# CTRL_MMR0_CFG0 register map
Vendor: Texas Instruments
Registers are 32-bit, read-write, reset 0x0 unless marked. A register's access mark holds for its fields unless they carry their own. Offsets are as the file gives them; [hi:lo] are bit positions; {n}, {i} and the like mark numbered series.

## CTRL_MMR0_CFG0 (part 8 of 10)
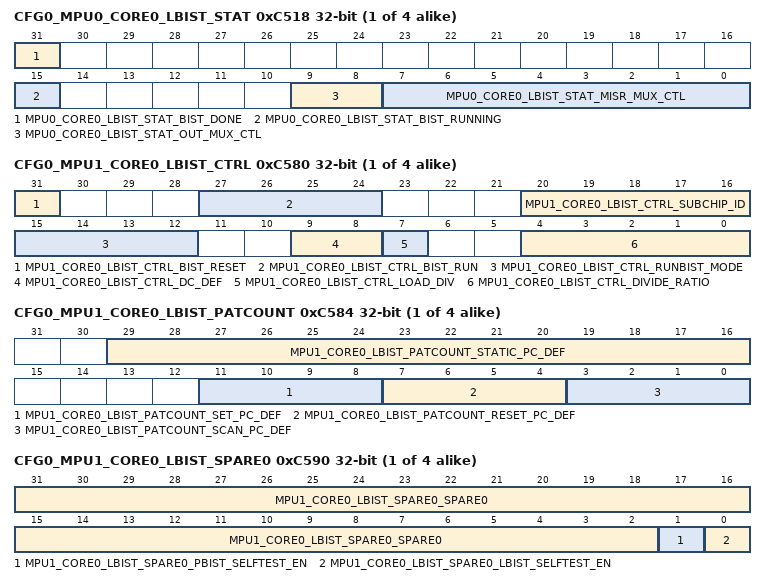
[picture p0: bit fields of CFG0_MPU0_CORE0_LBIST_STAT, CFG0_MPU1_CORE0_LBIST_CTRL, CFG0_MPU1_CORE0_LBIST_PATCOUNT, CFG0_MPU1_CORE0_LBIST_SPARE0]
{0xC518+0x20*i} CFG0_MPU0_CORE{i}_LBIST_STAT access per field (i=0..3) — Indicates LBIST status and provides MISR selection control
  [31] MPU0_CORE{i}_LBIST_STAT_BIST_DONE ro — LBIST is done
  [15] MPU0_CORE{i}_LBIST_STAT_BIST_RUNNING ro — LBIST is running
  [9:8] MPU0_CORE{i}_LBIST_STAT_OUT_MUX_CTL rw — Selects source of LBIST output 00 - LBIST IP PID value 01 - LBIST CTRL ID value 1x - MISR value
  [7:0] MPU0_CORE{i}_LBIST_STAT_MISR_MUX_CTL rw — Selects block of 32 MISR bits to read. A value of 0 selects a compacted 32-bit version of the full MISR. A value of 1-32 select a 32-bit segment of the MISR.
{0xC51C+0x20*i} CFG0_MPU0_CORE{i}_LBIST_MISR ro (i=0..3) — Contains LBIST MISR output value
  [31:0] MPU0_CORE{i}_LBIST_MISR_MISR_RESULT — 32-bits of MISR value selected by misr_mux_ctl
{0xC580+0x20*i} CFG0_MPU1_CORE{i}_LBIST_CTRL (i=0..3) — Configures and enables LBIST operation
  [31] MPU1_CORE{i}_LBIST_CTRL_BIST_RESET — Reset LBIST macro
  [27:24] MPU1_CORE{i}_LBIST_CTRL_BIST_RUN — Starts LBIST if all bits are 1
  [20:16] MPU1_CORE{i}_LBIST_CTRL_SUBCHIP_ID — Specifies which sub-chip is to be tested
  [15:12] MPU1_CORE{i}_LBIST_CTRL_RUNBIST_MODE — Runbist mode enable if all bits are 1
  [9:8] MPU1_CORE{i}_LBIST_CTRL_DC_DEF — Clock delay after scan_enable switching
  [7] MPU1_CORE{i}_LBIST_CTRL_LOAD_DIV — Loads LBIST clock divide ratio on transition from 0 to 1
  [4:0] MPU1_CORE{i}_LBIST_CTRL_DIVIDE_RATIO — LBIST clock divide ratio
{0xC584+0x20*i} CFG0_MPU1_CORE{i}_LBIST_PATCOUNT (i=0..3) — Specifies the number of LBIST patterns to run
  [29:16] MPU1_CORE{i}_LBIST_PATCOUNT_STATIC_PC_DEF — Number of stuck-at patterns to run
  [11:8] MPU1_CORE{i}_LBIST_PATCOUNT_SET_PC_DEF — Number of set patterns to run
  [7:4] MPU1_CORE{i}_LBIST_PATCOUNT_RESET_PC_DEF — Number of reset patterns to run
  [3:0] MPU1_CORE{i}_LBIST_PATCOUNT_SCAN_PC_DEF — Number of chain test patterns to run
{0xC588+0x20*i} CFG0_MPU1_CORE{i}_LBIST_SEED0 (i=0..3) — Specifies the 32 LSBs of the PRPG seed
  [31:0] MPU1_CORE{i}_LBIST_SEED0_PRPG_DEF — Initial seed for PRPG (bits 31:0)
{0xC58C+0x20*i} CFG0_MPU1_CORE{i}_LBIST_SEED1 (i=0..3) — Specifies the 21 MSBs of the PRPG seed
  [20:0] MPU1_CORE{i}_LBIST_SEED1_PRPG_DEF — Initial seed for PRPG (bits 52:32)
{0xC590+0x20*i} CFG0_MPU1_CORE{i}_LBIST_SPARE0 (i=0..3) — Spare LBIST control bits
  [31:2] MPU1_CORE{i}_LBIST_SPARE0_SPARE0 — LBIST spare bits
  [1] MPU1_CORE{i}_LBIST_SPARE0_PBIST_SELFTEST_EN — PBIST isolation control
  [0] MPU1_CORE{i}_LBIST_SPARE0_LBIST_SELFTEST_EN — LBIST isolation control
{0xC594+0x20*i} CFG0_MPU1_CORE{i}_LBIST_SPARE1 (i=0..3) — Spare LBIST control bits
  [31:0] MPU1_CORE{i}_LBIST_SPARE1_SPARE1 — LBIST spare bits
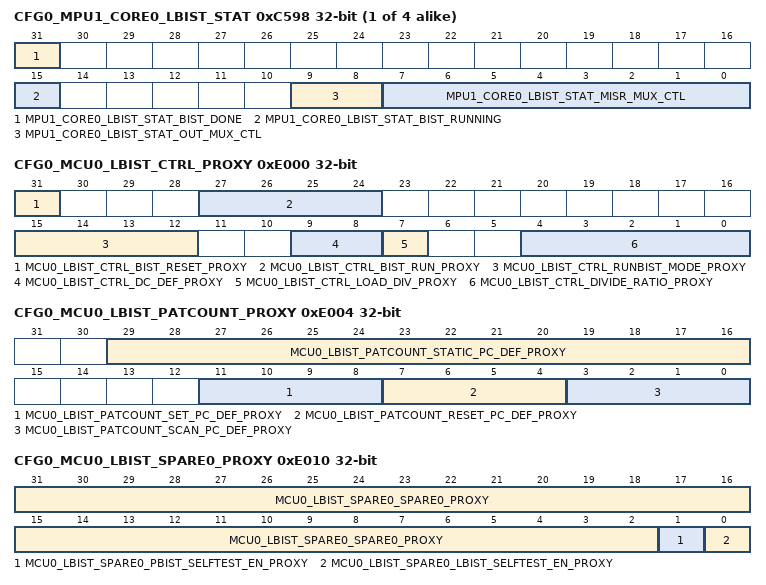
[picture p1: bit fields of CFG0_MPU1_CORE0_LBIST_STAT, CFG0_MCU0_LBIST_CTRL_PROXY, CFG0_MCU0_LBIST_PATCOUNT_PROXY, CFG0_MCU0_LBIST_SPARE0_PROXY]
{0xC598+0x20*i} CFG0_MPU1_CORE{i}_LBIST_STAT access per field (i=0..3) — Indicates LBIST status and provides MISR selection control
  [31] MPU1_CORE{i}_LBIST_STAT_BIST_DONE ro — LBIST is done
  [15] MPU1_CORE{i}_LBIST_STAT_BIST_RUNNING ro — LBIST is running
  [9:8] MPU1_CORE{i}_LBIST_STAT_OUT_MUX_CTL rw — Selects source of LBIST output 00 - LBIST IP PID value 01 - LBIST CTRL ID value 1x - MISR value
  [7:0] MPU1_CORE{i}_LBIST_STAT_MISR_MUX_CTL rw — Selects block of 32 MISR bits to read. A value of 0 selects a compacted 32-bit version of the full MISR. A value of 1-32 select a 32-bit segment of the MISR.
{0xC59C+0x20*i} CFG0_MPU1_CORE{i}_LBIST_MISR ro (i=0..3) — Contains LBIST MISR output value
  [31:0] MPU1_CORE{i}_LBIST_MISR_MISR_RESULT — 32-bits of MISR value selected by misr_mux_ctl
{0xC600+0x20*i} CFG0_MPU0_CORE{i}_LBIST_SIG ro (i=0..3) — Contains expected MISR output value
  [31:0] MPU0_CORE{i}_LBIST_SIG_MISR_SIG — MISR signature
{0xC680+0x20*i} CFG0_MPU1_CORE{i}_LBIST_SIG ro (i=0..3) — Contains expected MISR output value
  [31:0] MPU1_CORE{i}_LBIST_SIG_MISR_SIG — MISR signature
{0xD100+4i} CFG0_CLAIMREG_P3_R{i}_READONLY ro (i=0..13)
  [31:0] CLAIMREG_P3_R{i}_READONLY — Claim bits for Partition 3
0xE000 CFG0_MCU0_LBIST_CTRL_PROXY — Configures and enables LBIST operation
  [31] MCU0_LBIST_CTRL_BIST_RESET_PROXY — Reset LBIST macro
  [27:24] MCU0_LBIST_CTRL_BIST_RUN_PROXY — Starts LBIST if all bits are 1
  [15:12] MCU0_LBIST_CTRL_RUNBIST_MODE_PROXY — Runbist mode enable if all bits are 1
  [9:8] MCU0_LBIST_CTRL_DC_DEF_PROXY — Clock delay after scan_enable switching
  [7] MCU0_LBIST_CTRL_LOAD_DIV_PROXY — Loads LBIST clock divide ratio on transition from 0 to 1
  [4:0] MCU0_LBIST_CTRL_DIVIDE_RATIO_PROXY — LBIST clock divide ratio
0xE004 CFG0_MCU0_LBIST_PATCOUNT_PROXY — Specifies the number of LBIST patterns to run
  [29:16] MCU0_LBIST_PATCOUNT_STATIC_PC_DEF_PROXY — Number of stuck-at patterns to run
  [11:8] MCU0_LBIST_PATCOUNT_SET_PC_DEF_PROXY — Number of set patterns to run
  [7:4] MCU0_LBIST_PATCOUNT_RESET_PC_DEF_PROXY — Number of reset patterns to run
  [3:0] MCU0_LBIST_PATCOUNT_SCAN_PC_DEF_PROXY — Number of chain test patterns to run
0xE008 CFG0_MCU0_LBIST_SEED0_PROXY — Specifies the 32 LSBs of the PRPG seed
  [31:0] MCU0_LBIST_SEED0_PRPG_DEF_PROXY — Initial seed for PRPG (bits 31:0)
0xE00C CFG0_MCU0_LBIST_SEED1_PROXY — Specifies the 21 MSBs of the PRPG seed
  [20:0] MCU0_LBIST_SEED1_PRPG_DEF_PROXY — Initial seed for PRPG (bits 52:32)
0xE010 CFG0_MCU0_LBIST_SPARE0_PROXY — Spare LBIST control bits
  [31:2] MCU0_LBIST_SPARE0_SPARE0_PROXY — LBIST spare bits
  [1] MCU0_LBIST_SPARE0_PBIST_SELFTEST_EN_PROXY — PBIST isolation control
  [0] MCU0_LBIST_SPARE0_LBIST_SELFTEST_EN_PROXY — LBIST isolation control
0xE014 CFG0_MCU0_LBIST_SPARE1_PROXY — Spare LBIST control bits
  [31:0] MCU0_LBIST_SPARE1_SPARE1_PROXY — LBIST spare bits
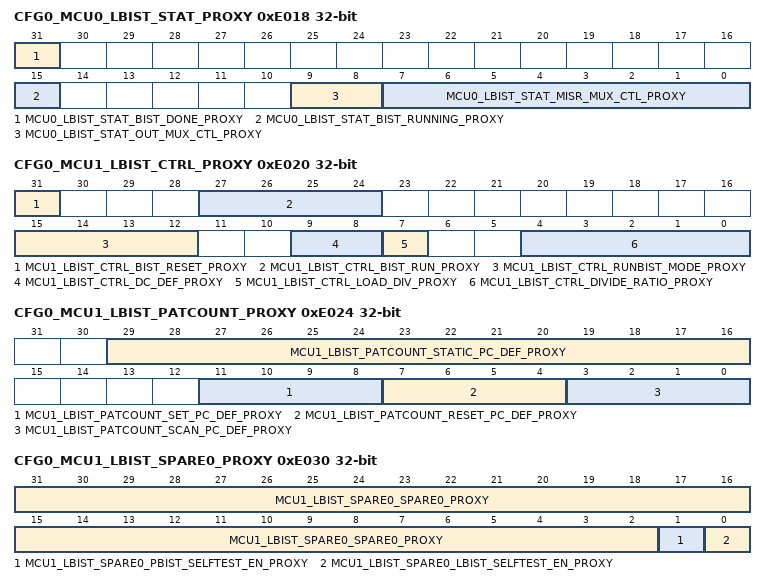
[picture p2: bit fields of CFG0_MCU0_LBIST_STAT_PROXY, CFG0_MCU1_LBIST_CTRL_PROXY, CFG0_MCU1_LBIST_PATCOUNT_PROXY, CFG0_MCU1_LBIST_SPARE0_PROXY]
0xE018 CFG0_MCU0_LBIST_STAT_PROXY access per field — Indicates LBIST status and provides MISR selection control
  [31] MCU0_LBIST_STAT_BIST_DONE_PROXY ro — LBIST is done
  [15] MCU0_LBIST_STAT_BIST_RUNNING_PROXY ro — LBIST is running
  [9:8] MCU0_LBIST_STAT_OUT_MUX_CTL_PROXY rw — Selects source of LBIST output 00 - LBIST IP PID value 01 - LBIST CTRL ID value 1x - MISR value
  [7:0] MCU0_LBIST_STAT_MISR_MUX_CTL_PROXY rw — Selects block of 32 MISR bits to read. A value of 0 selects a compacted 32-bit version of the full MISR. A value of 1-32 select a 32-bit segment of the MISR.
0xE01C CFG0_MCU0_LBIST_MISR_PROXY ro — Contains LBIST MISR output value
  [31:0] MCU0_LBIST_MISR_MISR_RESULT_PROXY — 32-bits of MISR value selected by misr_mux_ctl
0xE020 CFG0_MCU1_LBIST_CTRL_PROXY — Configures and enables LBIST operation
  [31] MCU1_LBIST_CTRL_BIST_RESET_PROXY — Reset LBIST macro
  [27:24] MCU1_LBIST_CTRL_BIST_RUN_PROXY — Starts LBIST if all bits are 1
  [15:12] MCU1_LBIST_CTRL_RUNBIST_MODE_PROXY — Runbist mode enable if all bits are 1
  [9:8] MCU1_LBIST_CTRL_DC_DEF_PROXY — Clock delay after scan_enable switching
  [7] MCU1_LBIST_CTRL_LOAD_DIV_PROXY — Loads LBIST clock divide ratio on transition from 0 to 1
  [4:0] MCU1_LBIST_CTRL_DIVIDE_RATIO_PROXY — LBIST clock divide ratio
0xE024 CFG0_MCU1_LBIST_PATCOUNT_PROXY — Specifies the number of LBIST patterns to run
  [29:16] MCU1_LBIST_PATCOUNT_STATIC_PC_DEF_PROXY — Number of stuck-at patterns to run
  [11:8] MCU1_LBIST_PATCOUNT_SET_PC_DEF_PROXY — Number of set patterns to run
  [7:4] MCU1_LBIST_PATCOUNT_RESET_PC_DEF_PROXY — Number of reset patterns to run
  [3:0] MCU1_LBIST_PATCOUNT_SCAN_PC_DEF_PROXY — Number of chain test patterns to run
0xE028 CFG0_MCU1_LBIST_SEED0_PROXY — Specifies the 32 LSBs of the PRPG seed
  [31:0] MCU1_LBIST_SEED0_PRPG_DEF_PROXY — Initial seed for PRPG (bits 31:0)
0xE02C CFG0_MCU1_LBIST_SEED1_PROXY — Specifies the 21 MSBs of the PRPG seed
  [20:0] MCU1_LBIST_SEED1_PRPG_DEF_PROXY — Initial seed for PRPG (bits 52:32)
0xE030 CFG0_MCU1_LBIST_SPARE0_PROXY — Spare LBIST control bits
  [31:2] MCU1_LBIST_SPARE0_SPARE0_PROXY — LBIST spare bits
  [1] MCU1_LBIST_SPARE0_PBIST_SELFTEST_EN_PROXY — PBIST isolation control
  [0] MCU1_LBIST_SPARE0_LBIST_SELFTEST_EN_PROXY — LBIST isolation control
0xE034 CFG0_MCU1_LBIST_SPARE1_PROXY — Spare LBIST control bits
  [31:0] MCU1_LBIST_SPARE1_SPARE1_PROXY — LBIST spare bits
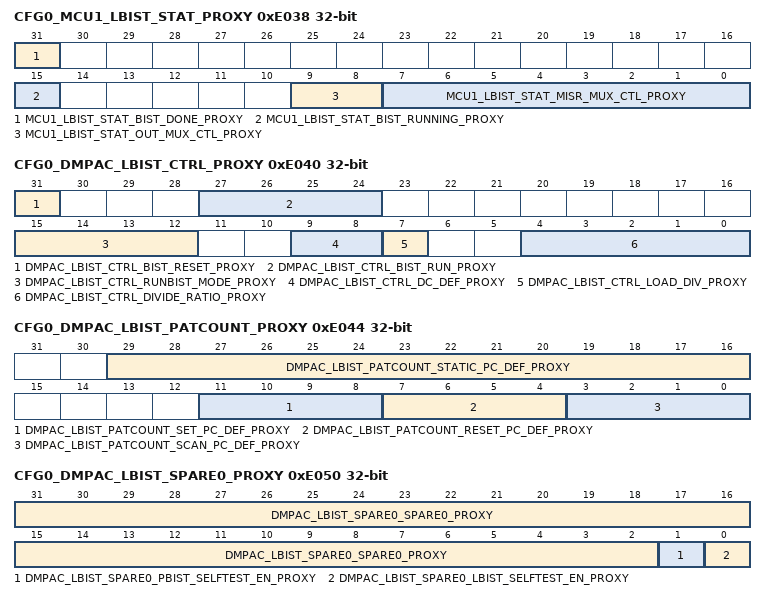
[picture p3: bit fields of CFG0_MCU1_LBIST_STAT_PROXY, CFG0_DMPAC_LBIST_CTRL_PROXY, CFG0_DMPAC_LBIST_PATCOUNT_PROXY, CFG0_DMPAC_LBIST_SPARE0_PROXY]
0xE038 CFG0_MCU1_LBIST_STAT_PROXY access per field — Indicates LBIST status and provides MISR selection control
  [31] MCU1_LBIST_STAT_BIST_DONE_PROXY ro — LBIST is done
  [15] MCU1_LBIST_STAT_BIST_RUNNING_PROXY ro — LBIST is running
  [9:8] MCU1_LBIST_STAT_OUT_MUX_CTL_PROXY rw — Selects source of LBIST output 00 - LBIST IP PID value 01 - LBIST CTRL ID value 1x - MISR value
  [7:0] MCU1_LBIST_STAT_MISR_MUX_CTL_PROXY rw — Selects block of 32 MISR bits to read. A value of 0 selects a compacted 32-bit version of the full MISR. A value of 1-32 select a 32-bit segment of the MISR.
0xE03C CFG0_MCU1_LBIST_MISR_PROXY ro — Contains LBIST MISR output value
  [31:0] MCU1_LBIST_MISR_MISR_RESULT_PROXY — 32-bits of MISR value selected by misr_mux_ctl
0xE040 CFG0_DMPAC_LBIST_CTRL_PROXY — Configures and enables LBIST operation
  [31] DMPAC_LBIST_CTRL_BIST_RESET_PROXY — Reset LBIST macro
  [27:24] DMPAC_LBIST_CTRL_BIST_RUN_PROXY — Starts LBIST if all bits are 1
  [15:12] DMPAC_LBIST_CTRL_RUNBIST_MODE_PROXY — Runbist mode enable if all bits are 1
  [9:8] DMPAC_LBIST_CTRL_DC_DEF_PROXY — Clock delay after scan_enable switching
  [7] DMPAC_LBIST_CTRL_LOAD_DIV_PROXY — Loads LBIST clock divide ratio on transition from 0 to 1
  [4:0] DMPAC_LBIST_CTRL_DIVIDE_RATIO_PROXY — LBIST clock divide ratio
0xE044 CFG0_DMPAC_LBIST_PATCOUNT_PROXY — Specifies the number of LBIST patterns to run
  [29:16] DMPAC_LBIST_PATCOUNT_STATIC_PC_DEF_PROXY — Number of stuck-at patterns to run
  [11:8] DMPAC_LBIST_PATCOUNT_SET_PC_DEF_PROXY — Number of set patterns to run
  [7:4] DMPAC_LBIST_PATCOUNT_RESET_PC_DEF_PROXY — Number of reset patterns to run
  [3:0] DMPAC_LBIST_PATCOUNT_SCAN_PC_DEF_PROXY — Number of chain test patterns to run
0xE048 CFG0_DMPAC_LBIST_SEED0_PROXY — Specifies the 32 LSBs of the PRPG seed
  [31:0] DMPAC_LBIST_SEED0_PRPG_DEF_PROXY — Initial seed for PRPG (bits 31:0)
0xE04C CFG0_DMPAC_LBIST_SEED1_PROXY — Specifies the 21 MSBs of the PRPG seed
  [20:0] DMPAC_LBIST_SEED1_PRPG_DEF_PROXY — Initial seed for PRPG (bits 52:32)
0xE050 CFG0_DMPAC_LBIST_SPARE0_PROXY — Spare LBIST control bits
  [31:2] DMPAC_LBIST_SPARE0_SPARE0_PROXY — LBIST spare bits
  [1] DMPAC_LBIST_SPARE0_PBIST_SELFTEST_EN_PROXY — PBIST isolation control
  [0] DMPAC_LBIST_SPARE0_LBIST_SELFTEST_EN_PROXY — LBIST isolation control
0xE054 CFG0_DMPAC_LBIST_SPARE1_PROXY — Spare LBIST control bits
  [31:0] DMPAC_LBIST_SPARE1_SPARE1_PROXY — LBIST spare bits
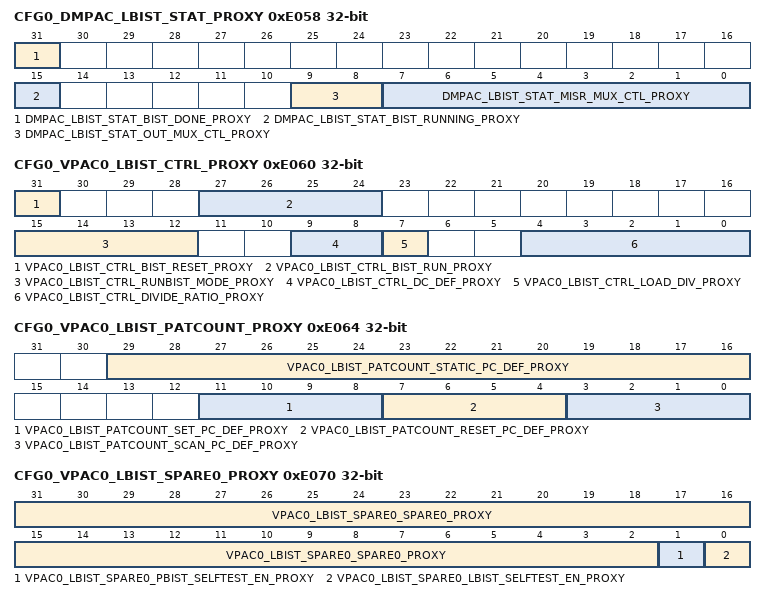
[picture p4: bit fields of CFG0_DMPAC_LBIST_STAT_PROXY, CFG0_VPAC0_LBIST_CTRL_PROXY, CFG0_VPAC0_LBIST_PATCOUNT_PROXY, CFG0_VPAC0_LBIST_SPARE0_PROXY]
0xE058 CFG0_DMPAC_LBIST_STAT_PROXY access per field — Indicates LBIST status and provides MISR selection control
  [31] DMPAC_LBIST_STAT_BIST_DONE_PROXY ro — LBIST is done
  [15] DMPAC_LBIST_STAT_BIST_RUNNING_PROXY ro — LBIST is running
  [9:8] DMPAC_LBIST_STAT_OUT_MUX_CTL_PROXY rw — Selects source of LBIST output 00 - LBIST IP PID value 01 - LBIST CTRL ID value 1x - MISR value
  [7:0] DMPAC_LBIST_STAT_MISR_MUX_CTL_PROXY rw — Selects block of 32 MISR bits to read. A value of 0 selects a compacted 32-bit version of the full MISR. A value of 1-32 select a 32-bit segment of the MISR.
0xE05C CFG0_DMPAC_LBIST_MISR_PROXY ro — Contains LBIST MISR output value
  [31:0] DMPAC_LBIST_MISR_MISR_RESULT_PROXY — 32-bits of MISR value selected by misr_mux_ctl
0xE060 CFG0_VPAC0_LBIST_CTRL_PROXY — Configures and enables LBIST operation
  [31] VPAC0_LBIST_CTRL_BIST_RESET_PROXY — Reset LBIST macro
  [27:24] VPAC0_LBIST_CTRL_BIST_RUN_PROXY — Starts LBIST if all bits are 1
  [15:12] VPAC0_LBIST_CTRL_RUNBIST_MODE_PROXY — Runbist mode enable if all bits are 1
  [9:8] VPAC0_LBIST_CTRL_DC_DEF_PROXY — Clock delay after scan_enable switching
  [7] VPAC0_LBIST_CTRL_LOAD_DIV_PROXY — Loads LBIST clock divide ratio on transition from 0 to 1
  [4:0] VPAC0_LBIST_CTRL_DIVIDE_RATIO_PROXY — LBIST clock divide ratio
0xE064 CFG0_VPAC0_LBIST_PATCOUNT_PROXY — Specifies the number of LBIST patterns to run
  [29:16] VPAC0_LBIST_PATCOUNT_STATIC_PC_DEF_PROXY — Number of stuck-at patterns to run
  [11:8] VPAC0_LBIST_PATCOUNT_SET_PC_DEF_PROXY — Number of set patterns to run
  [7:4] VPAC0_LBIST_PATCOUNT_RESET_PC_DEF_PROXY — Number of reset patterns to run
  [3:0] VPAC0_LBIST_PATCOUNT_SCAN_PC_DEF_PROXY — Number of chain test patterns to run
0xE068 CFG0_VPAC0_LBIST_SEED0_PROXY — Specifies the 32 LSBs of the PRPG seed
  [31:0] VPAC0_LBIST_SEED0_PRPG_DEF_PROXY — Initial seed for PRPG (bits 31:0)
0xE06C CFG0_VPAC0_LBIST_SEED1_PROXY — Specifies the 21 MSBs of the PRPG seed
  [20:0] VPAC0_LBIST_SEED1_PRPG_DEF_PROXY — Initial seed for PRPG (bits 52:32)
0xE070 CFG0_VPAC0_LBIST_SPARE0_PROXY — Spare LBIST control bits
  [31:2] VPAC0_LBIST_SPARE0_SPARE0_PROXY — LBIST spare bits
  [1] VPAC0_LBIST_SPARE0_PBIST_SELFTEST_EN_PROXY — PBIST isolation control
  [0] VPAC0_LBIST_SPARE0_LBIST_SELFTEST_EN_PROXY — LBIST isolation control
0xE074 CFG0_VPAC0_LBIST_SPARE1_PROXY — Spare LBIST control bits
  [31:0] VPAC0_LBIST_SPARE1_SPARE1_PROXY — LBIST spare bits
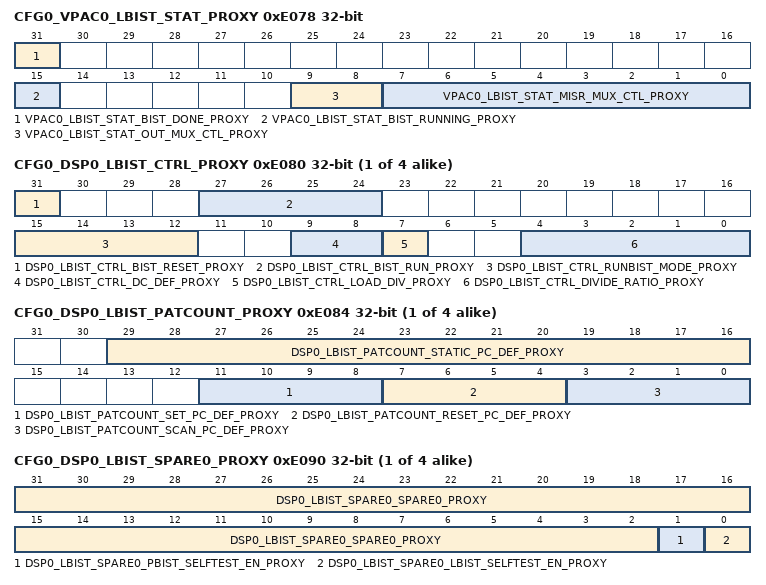
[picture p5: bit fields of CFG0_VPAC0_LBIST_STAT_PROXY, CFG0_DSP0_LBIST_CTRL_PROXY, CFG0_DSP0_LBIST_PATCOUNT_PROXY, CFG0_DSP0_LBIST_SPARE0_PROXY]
0xE078 CFG0_VPAC0_LBIST_STAT_PROXY access per field — Indicates LBIST status and provides MISR selection control
  [31] VPAC0_LBIST_STAT_BIST_DONE_PROXY ro — LBIST is done
  [15] VPAC0_LBIST_STAT_BIST_RUNNING_PROXY ro — LBIST is running
  [9:8] VPAC0_LBIST_STAT_OUT_MUX_CTL_PROXY rw — Selects source of LBIST output 00 - LBIST IP PID value 01 - LBIST CTRL ID value 1x - MISR value
  [7:0] VPAC0_LBIST_STAT_MISR_MUX_CTL_PROXY rw — Selects block of 32 MISR bits to read. A value of 0 selects a compacted 32-bit version of the full MISR. A value of 1-32 select a 32-bit segment of the MISR.
0xE07C CFG0_VPAC0_LBIST_MISR_PROXY ro — Contains LBIST MISR output value
  [31:0] VPAC0_LBIST_MISR_MISR_RESULT_PROXY — 32-bits of MISR value selected by misr_mux_ctl
{0xE080+0x20*i} CFG0_DSP{i}_LBIST_CTRL_PROXY (i=0..3) — Configures and enables LBIST operation
  [31] DSP{i}_LBIST_CTRL_BIST_RESET_PROXY — Reset LBIST macro
  [27:24] DSP{i}_LBIST_CTRL_BIST_RUN_PROXY — Starts LBIST if all bits are 1
  [15:12] DSP{i}_LBIST_CTRL_RUNBIST_MODE_PROXY — Runbist mode enable if all bits are 1
  [9:8] DSP{i}_LBIST_CTRL_DC_DEF_PROXY — Clock delay after scan_enable switching
  [7] DSP{i}_LBIST_CTRL_LOAD_DIV_PROXY — Loads LBIST clock divide ratio on transition from 0 to 1
  [4:0] DSP{i}_LBIST_CTRL_DIVIDE_RATIO_PROXY — LBIST clock divide ratio
{0xE084+0x20*i} CFG0_DSP{i}_LBIST_PATCOUNT_PROXY (i=0..3) — Specifies the number of LBIST patterns to run
  [29:16] DSP{i}_LBIST_PATCOUNT_STATIC_PC_DEF_PROXY — Number of stuck-at patterns to run
  [11:8] DSP{i}_LBIST_PATCOUNT_SET_PC_DEF_PROXY — Number of set patterns to run
  [7:4] DSP{i}_LBIST_PATCOUNT_RESET_PC_DEF_PROXY — Number of reset patterns to run
  [3:0] DSP{i}_LBIST_PATCOUNT_SCAN_PC_DEF_PROXY — Number of chain test patterns to run
{0xE088+0x20*i} CFG0_DSP{i}_LBIST_SEED0_PROXY (i=0..3) — Specifies the 32 LSBs of the PRPG seed
  [31:0] DSP{i}_LBIST_SEED0_PRPG_DEF_PROXY — Initial seed for PRPG (bits 31:0)
{0xE08C+0x20*i} CFG0_DSP{i}_LBIST_SEED1_PROXY (i=0..3) — Specifies the 21 MSBs of the PRPG seed
  [20:0] DSP{i}_LBIST_SEED1_PRPG_DEF_PROXY — Initial seed for PRPG (bits 52:32)
{0xE090+0x20*i} CFG0_DSP{i}_LBIST_SPARE0_PROXY (i=0..3) — Spare LBIST control bits
  [31:2] DSP{i}_LBIST_SPARE0_SPARE0_PROXY — LBIST spare bits
  [1] DSP{i}_LBIST_SPARE0_PBIST_SELFTEST_EN_PROXY — PBIST isolation control
  [0] DSP{i}_LBIST_SPARE0_LBIST_SELFTEST_EN_PROXY — LBIST isolation control
{0xE094+0x20*i} CFG0_DSP{i}_LBIST_SPARE1_PROXY (i=0..3) — Spare LBIST control bits
  [31:0] DSP{i}_LBIST_SPARE1_SPARE1_PROXY — LBIST spare bits
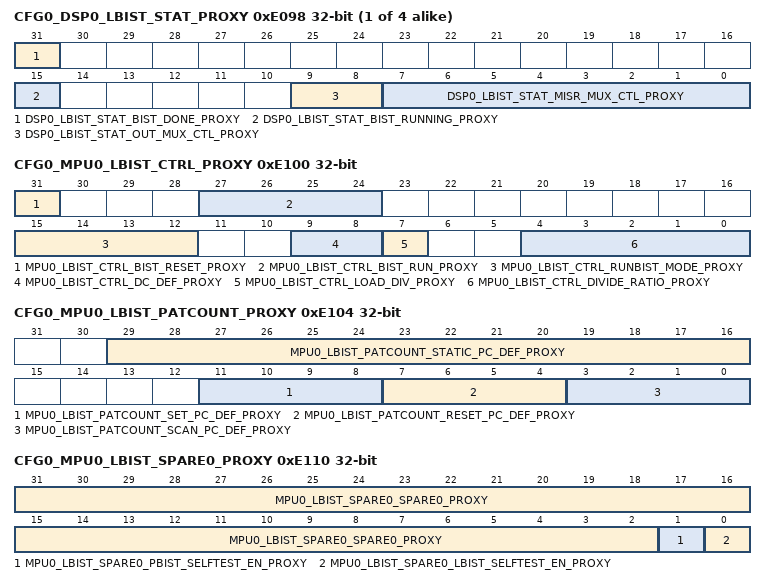
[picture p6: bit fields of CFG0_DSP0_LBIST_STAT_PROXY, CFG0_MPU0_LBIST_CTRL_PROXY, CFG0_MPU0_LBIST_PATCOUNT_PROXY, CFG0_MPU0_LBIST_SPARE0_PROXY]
{0xE098+0x20*i} CFG0_DSP{i}_LBIST_STAT_PROXY access per field (i=0..3) — Indicates LBIST status and provides MISR selection control
  [31] DSP{i}_LBIST_STAT_BIST_DONE_PROXY ro — LBIST is done
  [15] DSP{i}_LBIST_STAT_BIST_RUNNING_PROXY ro — LBIST is running
  [9:8] DSP{i}_LBIST_STAT_OUT_MUX_CTL_PROXY rw — Selects source of LBIST output 00 - LBIST IP PID value 01 - LBIST CTRL ID value 1x - MISR value
  [7:0] DSP{i}_LBIST_STAT_MISR_MUX_CTL_PROXY rw — Selects block of 32 MISR bits to read. A value of 0 selects a compacted 32-bit version of the full MISR. A value of 1-32 select a 32-bit segment of the MISR.
{0xE09C+0x20*i} CFG0_DSP{i}_LBIST_MISR_PROXY ro (i=0..3) — Contains LBIST MISR output value
  [31:0] DSP{i}_LBIST_MISR_MISR_RESULT_PROXY — 32-bits of MISR value selected by misr_mux_ctl
0xE100 CFG0_MPU0_LBIST_CTRL_PROXY — Configures and enables LBIST operation
  [31] MPU0_LBIST_CTRL_BIST_RESET_PROXY — Reset LBIST macro
  [27:24] MPU0_LBIST_CTRL_BIST_RUN_PROXY — Starts LBIST if all bits are 1
  [15:12] MPU0_LBIST_CTRL_RUNBIST_MODE_PROXY — Runbist mode enable if all bits are 1
  [9:8] MPU0_LBIST_CTRL_DC_DEF_PROXY — Clock delay after scan_enable switching
  [7] MPU0_LBIST_CTRL_LOAD_DIV_PROXY — Loads LBIST clock divide ratio on transition from 0 to 1
  [4:0] MPU0_LBIST_CTRL_DIVIDE_RATIO_PROXY — LBIST clock divide ratio
0xE104 CFG0_MPU0_LBIST_PATCOUNT_PROXY — Specifies the number of LBIST patterns to run
  [29:16] MPU0_LBIST_PATCOUNT_STATIC_PC_DEF_PROXY — Number of stuck-at patterns to run
  [11:8] MPU0_LBIST_PATCOUNT_SET_PC_DEF_PROXY — Number of set patterns to run
  [7:4] MPU0_LBIST_PATCOUNT_RESET_PC_DEF_PROXY — Number of reset patterns to run
  [3:0] MPU0_LBIST_PATCOUNT_SCAN_PC_DEF_PROXY — Number of chain test patterns to run
0xE108 CFG0_MPU0_LBIST_SEED0_PROXY — Specifies the 32 LSBs of the PRPG seed
  [31:0] MPU0_LBIST_SEED0_PRPG_DEF_PROXY — Initial seed for PRPG (bits 31:0)
0xE10C CFG0_MPU0_LBIST_SEED1_PROXY — Specifies the 21 MSBs of the PRPG seed
  [20:0] MPU0_LBIST_SEED1_PRPG_DEF_PROXY — Initial seed for PRPG (bits 52:32)
0xE110 CFG0_MPU0_LBIST_SPARE0_PROXY — Spare LBIST control bits
  [31:2] MPU0_LBIST_SPARE0_SPARE0_PROXY — LBIST spare bits
  [1] MPU0_LBIST_SPARE0_PBIST_SELFTEST_EN_PROXY — PBIST isolation control
  [0] MPU0_LBIST_SPARE0_LBIST_SELFTEST_EN_PROXY — LBIST isolation control
0xE114 CFG0_MPU0_LBIST_SPARE1_PROXY — Spare LBIST control bits
  [31:0] MPU0_LBIST_SPARE1_SPARE1_PROXY — LBIST spare bits
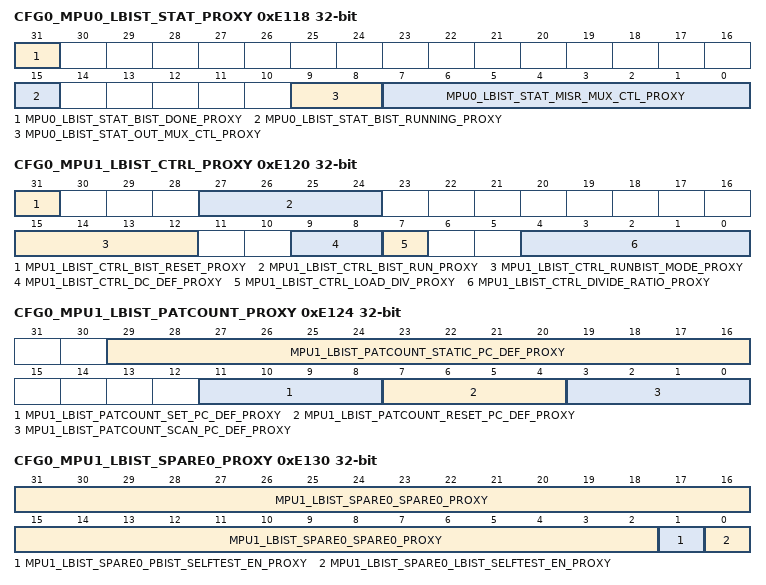
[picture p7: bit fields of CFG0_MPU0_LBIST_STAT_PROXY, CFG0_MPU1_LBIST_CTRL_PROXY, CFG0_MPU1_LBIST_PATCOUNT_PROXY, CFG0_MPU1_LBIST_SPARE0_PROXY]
0xE118 CFG0_MPU0_LBIST_STAT_PROXY access per field — Indicates LBIST status and provides MISR selection control
  [31] MPU0_LBIST_STAT_BIST_DONE_PROXY ro — LBIST is done
  [15] MPU0_LBIST_STAT_BIST_RUNNING_PROXY ro — LBIST is running
  [9:8] MPU0_LBIST_STAT_OUT_MUX_CTL_PROXY rw — Selects source of LBIST output 00 - LBIST IP PID value 01 - LBIST CTRL ID value 1x - MISR value
  [7:0] MPU0_LBIST_STAT_MISR_MUX_CTL_PROXY rw — Selects block of 32 MISR bits to read. A value of 0 selects a compacted 32-bit version of the full MISR. A value of 1-32 select a 32-bit segment of the MISR.
0xE11C CFG0_MPU0_LBIST_MISR_PROXY ro — Contains LBIST MISR output value
  [31:0] MPU0_LBIST_MISR_MISR_RESULT_PROXY — 32-bits of MISR value selected by misr_mux_ctl
0xE120 CFG0_MPU1_LBIST_CTRL_PROXY — Configures and enables LBIST operation
  [31] MPU1_LBIST_CTRL_BIST_RESET_PROXY — Reset LBIST macro
  [27:24] MPU1_LBIST_CTRL_BIST_RUN_PROXY — Starts LBIST if all bits are 1
  [15:12] MPU1_LBIST_CTRL_RUNBIST_MODE_PROXY — Runbist mode enable if all bits are 1
  [9:8] MPU1_LBIST_CTRL_DC_DEF_PROXY — Clock delay after scan_enable switching
  [7] MPU1_LBIST_CTRL_LOAD_DIV_PROXY — Loads LBIST clock divide ratio on transition from 0 to 1
  [4:0] MPU1_LBIST_CTRL_DIVIDE_RATIO_PROXY — LBIST clock divide ratio
0xE124 CFG0_MPU1_LBIST_PATCOUNT_PROXY — Specifies the number of LBIST patterns to run
  [29:16] MPU1_LBIST_PATCOUNT_STATIC_PC_DEF_PROXY — Number of stuck-at patterns to run
  [11:8] MPU1_LBIST_PATCOUNT_SET_PC_DEF_PROXY — Number of set patterns to run
  [7:4] MPU1_LBIST_PATCOUNT_RESET_PC_DEF_PROXY — Number of reset patterns to run
  [3:0] MPU1_LBIST_PATCOUNT_SCAN_PC_DEF_PROXY — Number of chain test patterns to run
0xE128 CFG0_MPU1_LBIST_SEED0_PROXY — Specifies the 32 LSBs of the PRPG seed
  [31:0] MPU1_LBIST_SEED0_PRPG_DEF_PROXY — Initial seed for PRPG (bits 31:0)
0xE12C CFG0_MPU1_LBIST_SEED1_PROXY — Specifies the 21 MSBs of the PRPG seed
  [20:0] MPU1_LBIST_SEED1_PRPG_DEF_PROXY — Initial seed for PRPG (bits 52:32)
0xE130 CFG0_MPU1_LBIST_SPARE0_PROXY — Spare LBIST control bits
  [31:2] MPU1_LBIST_SPARE0_SPARE0_PROXY — LBIST spare bits
  [1] MPU1_LBIST_SPARE0_PBIST_SELFTEST_EN_PROXY — PBIST isolation control
  [0] MPU1_LBIST_SPARE0_LBIST_SELFTEST_EN_PROXY — LBIST isolation control
0xE134 CFG0_MPU1_LBIST_SPARE1_PROXY — Spare LBIST control bits
  [31:0] MPU1_LBIST_SPARE1_SPARE1_PROXY — LBIST spare bits
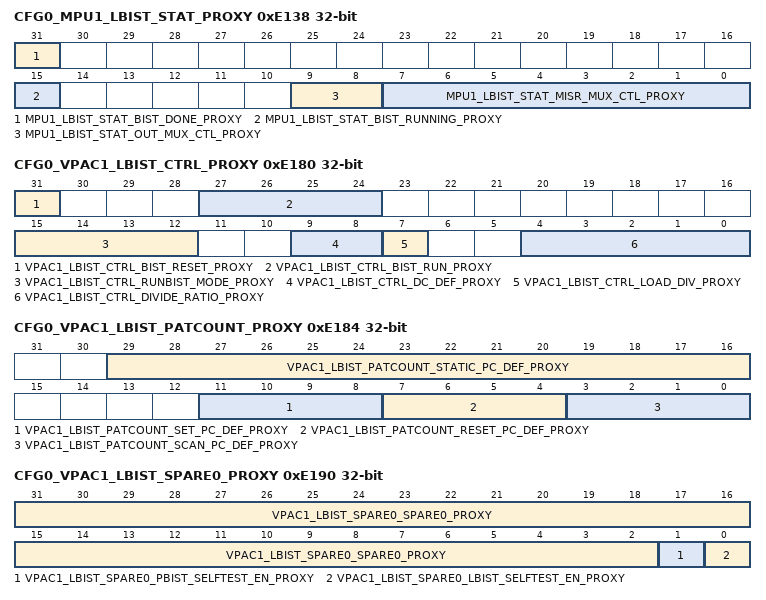
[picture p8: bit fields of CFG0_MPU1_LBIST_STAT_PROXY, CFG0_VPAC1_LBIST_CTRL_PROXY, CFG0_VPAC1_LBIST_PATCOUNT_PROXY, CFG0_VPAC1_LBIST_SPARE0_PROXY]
0xE138 CFG0_MPU1_LBIST_STAT_PROXY access per field — Indicates LBIST status and provides MISR selection control
  [31] MPU1_LBIST_STAT_BIST_DONE_PROXY ro — LBIST is done
  [15] MPU1_LBIST_STAT_BIST_RUNNING_PROXY ro — LBIST is running
  [9:8] MPU1_LBIST_STAT_OUT_MUX_CTL_PROXY rw — Selects source of LBIST output 00 - LBIST IP PID value 01 - LBIST CTRL ID value 1x - MISR value
  [7:0] MPU1_LBIST_STAT_MISR_MUX_CTL_PROXY rw — Selects block of 32 MISR bits to read. A value of 0 selects a compacted 32-bit version of the full MISR. A value of 1-32 select a 32-bit segment of the MISR.
0xE13C CFG0_MPU1_LBIST_MISR_PROXY ro — Contains LBIST MISR output value
  [31:0] MPU1_LBIST_MISR_MISR_RESULT_PROXY — 32-bits of MISR value selected by misr_mux_ctl
0xE180 CFG0_VPAC1_LBIST_CTRL_PROXY — Configures and enables LBIST operation
  [31] VPAC1_LBIST_CTRL_BIST_RESET_PROXY — Reset LBIST macro
  [27:24] VPAC1_LBIST_CTRL_BIST_RUN_PROXY — Starts LBIST if all bits are 1
  [15:12] VPAC1_LBIST_CTRL_RUNBIST_MODE_PROXY — Runbist mode enable if all bits are 1
  [9:8] VPAC1_LBIST_CTRL_DC_DEF_PROXY — Clock delay after scan_enable switching
  [7] VPAC1_LBIST_CTRL_LOAD_DIV_PROXY — Loads LBIST clock divide ratio on transition from 0 to 1
  [4:0] VPAC1_LBIST_CTRL_DIVIDE_RATIO_PROXY — LBIST clock divide ratio
0xE184 CFG0_VPAC1_LBIST_PATCOUNT_PROXY — Specifies the number of LBIST patterns to run
  [29:16] VPAC1_LBIST_PATCOUNT_STATIC_PC_DEF_PROXY — Number of stuck-at patterns to run
  [11:8] VPAC1_LBIST_PATCOUNT_SET_PC_DEF_PROXY — Number of set patterns to run
  [7:4] VPAC1_LBIST_PATCOUNT_RESET_PC_DEF_PROXY — Number of reset patterns to run
  [3:0] VPAC1_LBIST_PATCOUNT_SCAN_PC_DEF_PROXY — Number of chain test patterns to run
0xE188 CFG0_VPAC1_LBIST_SEED0_PROXY — Specifies the 32 LSBs of the PRPG seed
  [31:0] VPAC1_LBIST_SEED0_PRPG_DEF_PROXY — Initial seed for PRPG (bits 31:0)
0xE18C CFG0_VPAC1_LBIST_SEED1_PROXY — Specifies the 21 MSBs of the PRPG seed
  [20:0] VPAC1_LBIST_SEED1_PRPG_DEF_PROXY — Initial seed for PRPG (bits 52:32)
0xE190 CFG0_VPAC1_LBIST_SPARE0_PROXY — Spare LBIST control bits
  [31:2] VPAC1_LBIST_SPARE0_SPARE0_PROXY — LBIST spare bits
  [1] VPAC1_LBIST_SPARE0_PBIST_SELFTEST_EN_PROXY — PBIST isolation control
  [0] VPAC1_LBIST_SPARE0_LBIST_SELFTEST_EN_PROXY — LBIST isolation control
0xE194 CFG0_VPAC1_LBIST_SPARE1_PROXY — Spare LBIST control bits
  [31:0] VPAC1_LBIST_SPARE1_SPARE1_PROXY — LBIST spare bits
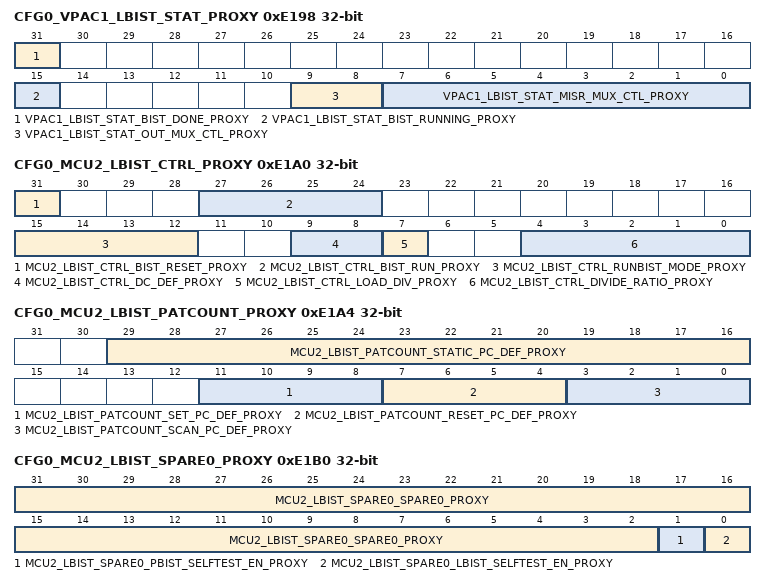
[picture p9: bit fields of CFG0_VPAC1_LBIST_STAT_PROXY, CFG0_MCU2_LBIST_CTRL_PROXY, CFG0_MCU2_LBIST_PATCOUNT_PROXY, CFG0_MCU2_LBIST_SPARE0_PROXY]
0xE198 CFG0_VPAC1_LBIST_STAT_PROXY access per field — Indicates LBIST status and provides MISR selection control
  [31] VPAC1_LBIST_STAT_BIST_DONE_PROXY ro — LBIST is done
  [15] VPAC1_LBIST_STAT_BIST_RUNNING_PROXY ro — LBIST is running
  [9:8] VPAC1_LBIST_STAT_OUT_MUX_CTL_PROXY rw — Selects source of LBIST output 00 - LBIST IP PID value 01 - LBIST CTRL ID value 1x - MISR value
  [7:0] VPAC1_LBIST_STAT_MISR_MUX_CTL_PROXY rw — Selects block of 32 MISR bits to read. A value of 0 selects a compacted 32-bit version of the full MISR. A value of 1-32 select a 32-bit segment of the MISR.
0xE19C CFG0_VPAC1_LBIST_MISR_PROXY ro — Contains LBIST MISR output value
  [31:0] VPAC1_LBIST_MISR_MISR_RESULT_PROXY — 32-bits of MISR value selected by misr_mux_ctl
0xE1A0 CFG0_MCU2_LBIST_CTRL_PROXY — Configures and enables LBIST operation
  [31] MCU2_LBIST_CTRL_BIST_RESET_PROXY — Reset LBIST macro
  [27:24] MCU2_LBIST_CTRL_BIST_RUN_PROXY — Starts LBIST if all bits are 1
  [15:12] MCU2_LBIST_CTRL_RUNBIST_MODE_PROXY — Runbist mode enable if all bits are 1
  [9:8] MCU2_LBIST_CTRL_DC_DEF_PROXY — Clock delay after scan_enable switching
  [7] MCU2_LBIST_CTRL_LOAD_DIV_PROXY — Loads LBIST clock divide ratio on transition from 0 to 1
  [4:0] MCU2_LBIST_CTRL_DIVIDE_RATIO_PROXY — LBIST clock divide ratio
0xE1A4 CFG0_MCU2_LBIST_PATCOUNT_PROXY — Specifies the number of LBIST patterns to run
  [29:16] MCU2_LBIST_PATCOUNT_STATIC_PC_DEF_PROXY — Number of stuck-at patterns to run
  [11:8] MCU2_LBIST_PATCOUNT_SET_PC_DEF_PROXY — Number of set patterns to run
  [7:4] MCU2_LBIST_PATCOUNT_RESET_PC_DEF_PROXY — Number of reset patterns to run
  [3:0] MCU2_LBIST_PATCOUNT_SCAN_PC_DEF_PROXY — Number of chain test patterns to run
0xE1A8 CFG0_MCU2_LBIST_SEED0_PROXY — Specifies the 32 LSBs of the PRPG seed
  [31:0] MCU2_LBIST_SEED0_PRPG_DEF_PROXY — Initial seed for PRPG (bits 31:0)
0xE1AC CFG0_MCU2_LBIST_SEED1_PROXY — Specifies the 21 MSBs of the PRPG seed
  [20:0] MCU2_LBIST_SEED1_PRPG_DEF_PROXY — Initial seed for PRPG (bits 52:32)
0xE1B0 CFG0_MCU2_LBIST_SPARE0_PROXY — Spare LBIST control bits
  [31:2] MCU2_LBIST_SPARE0_SPARE0_PROXY — LBIST spare bits
  [1] MCU2_LBIST_SPARE0_PBIST_SELFTEST_EN_PROXY — PBIST isolation control
  [0] MCU2_LBIST_SPARE0_LBIST_SELFTEST_EN_PROXY — LBIST isolation control
0xE1B4 CFG0_MCU2_LBIST_SPARE1_PROXY — Spare LBIST control bits
  [31:0] MCU2_LBIST_SPARE1_SPARE1_PROXY — LBIST spare bits
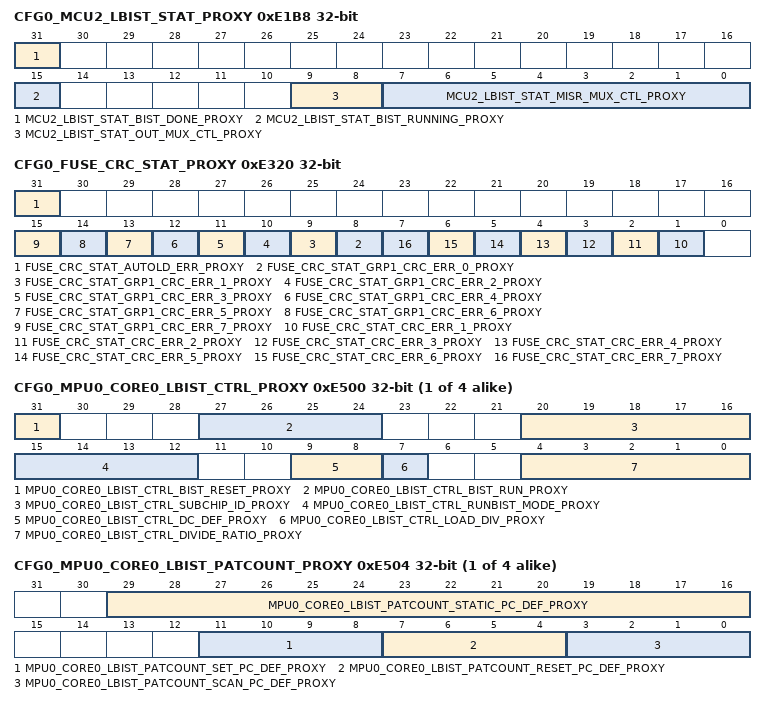
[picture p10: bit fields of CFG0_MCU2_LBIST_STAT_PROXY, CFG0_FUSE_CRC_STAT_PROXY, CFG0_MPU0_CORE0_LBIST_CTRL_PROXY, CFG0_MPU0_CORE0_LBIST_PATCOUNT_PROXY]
0xE1B8 CFG0_MCU2_LBIST_STAT_PROXY access per field — Indicates LBIST status and provides MISR selection control
  [31] MCU2_LBIST_STAT_BIST_DONE_PROXY ro — LBIST is done
  [15] MCU2_LBIST_STAT_BIST_RUNNING_PROXY ro — LBIST is running
  [9:8] MCU2_LBIST_STAT_OUT_MUX_CTL_PROXY rw — Selects source of LBIST output 00 - LBIST IP PID value 01 - LBIST CTRL ID value 1x - MISR value
  [7:0] MCU2_LBIST_STAT_MISR_MUX_CTL_PROXY rw — Selects block of 32 MISR bits to read. A value of 0 selects a compacted 32-bit version of the full MISR. A value of 1-32 select a 32-bit segment of the MISR.
0xE1BC CFG0_MCU2_LBIST_MISR_PROXY ro — Contains LBIST MISR output value
  [31:0] MCU2_LBIST_MISR_MISR_RESULT_PROXY — 32-bits of MISR value selected by misr_mux_ctl
0xE280 CFG0_MCU0_LBIST_SIG_PROXY ro — Contains expected MISR output value
  [31:0] MCU0_LBIST_SIG_MISR_SIG_PROXY — MISR signature
0xE284 CFG0_MCU1_LBIST_SIG_PROXY ro — Contains expected MISR output value
  [31:0] MCU1_LBIST_SIG_MISR_SIG_PROXY — MISR signature
0xE288 CFG0_DMPAC_LBIST_SIG_PROXY ro — Contains expected MISR output value
  [31:0] DMPAC_LBIST_SIG_MISR_SIG_PROXY — MISR signature
0xE28C CFG0_VPAC0_LBIST_SIG_PROXY ro — Contains expected MISR output value
  [31:0] VPAC0_LBIST_SIG_MISR_SIG_PROXY — MISR signature
{0xE290+4i} CFG0_DSP{i}_LBIST_SIG_PROXY ro (i=0..3) — Contains expected MISR output value
  [31:0] DSP{i}_LBIST_SIG_MISR_SIG_PROXY — MISR signature
0xE2A0 CFG0_MPU0_LBIST_SIG_PROXY ro — Contains expected MISR output value
  [31:0] MPU0_LBIST_SIG_MISR_SIG_PROXY — MISR signature
0xE2A4 CFG0_MPU1_LBIST_SIG_PROXY ro — Contains expected MISR output value
  [31:0] MPU1_LBIST_SIG_MISR_SIG_PROXY — MISR signature
0xE2B0 CFG0_VPAC1_LBIST_SIG_PROXY ro — Contains expected MISR output value
  [31:0] VPAC1_LBIST_SIG_MISR_SIG_PROXY — MISR signature
0xE2C0 CFG0_MCU2_LBIST_SIG_PROXY ro — Contains expected MISR output value
  [31:0] MCU2_LBIST_SIG_MISR_SIG_PROXY — MISR signature
0xE320 CFG0_FUSE_CRC_STAT_PROXY ro — Indicates status of fuse chain CRC
  [31] FUSE_CRC_STAT_AUTOLD_ERR_PROXY — Indicates eFuse autoload or programmation error on any chain
  [n+8] FUSE_CRC_STAT_GRP1_CRC_ERR_{n}_PROXY (n=0..7) — Indicates eFuse CRC error on group1 chain {n}
  [n] FUSE_CRC_STAT_CRC_ERR_{n}_PROXY (n=1..7) — Indicates eFuse CRC error on chain {n}
{0xE500+0x20*i} CFG0_MPU0_CORE{i}_LBIST_CTRL_PROXY (i=0..3) — Configures and enables LBIST operation
  [31] MPU0_CORE{i}_LBIST_CTRL_BIST_RESET_PROXY — Reset LBIST macro
  [27:24] MPU0_CORE{i}_LBIST_CTRL_BIST_RUN_PROXY — Starts LBIST if all bits are 1
  [20:16] MPU0_CORE{i}_LBIST_CTRL_SUBCHIP_ID_PROXY — Specifies which sub-chip is to be tested
  [15:12] MPU0_CORE{i}_LBIST_CTRL_RUNBIST_MODE_PROXY — Runbist mode enable if all bits are 1
  [9:8] MPU0_CORE{i}_LBIST_CTRL_DC_DEF_PROXY — Clock delay after scan_enable switching
  [7] MPU0_CORE{i}_LBIST_CTRL_LOAD_DIV_PROXY — Loads LBIST clock divide ratio on transition from 0 to 1
  [4:0] MPU0_CORE{i}_LBIST_CTRL_DIVIDE_RATIO_PROXY — LBIST clock divide ratio
{0xE504+0x20*i} CFG0_MPU0_CORE{i}_LBIST_PATCOUNT_PROXY (i=0..3) — Specifies the number of LBIST patterns to run
  [29:16] MPU0_CORE{i}_LBIST_PATCOUNT_STATIC_PC_DEF_PROXY — Number of stuck-at patterns to run
  [11:8] MPU0_CORE{i}_LBIST_PATCOUNT_SET_PC_DEF_PROXY — Number of set patterns to run
  [7:4] MPU0_CORE{i}_LBIST_PATCOUNT_RESET_PC_DEF_PROXY — Number of reset patterns to run
  [3:0] MPU0_CORE{i}_LBIST_PATCOUNT_SCAN_PC_DEF_PROXY — Number of chain test patterns to run
{0xE508+0x20*i} CFG0_MPU0_CORE{i}_LBIST_SEED0_PROXY (i=0..3) — Specifies the 32 LSBs of the PRPG seed
  [31:0] MPU0_CORE{i}_LBIST_SEED0_PRPG_DEF_PROXY — Initial seed for PRPG (bits 31:0)
{0xE50C+0x20*i} CFG0_MPU0_CORE{i}_LBIST_SEED1_PROXY (i=0..3) — Specifies the 21 MSBs of the PRPG seed
  [20:0] MPU0_CORE{i}_LBIST_SEED1_PRPG_DEF_PROXY — Initial seed for PRPG (bits 52:32)
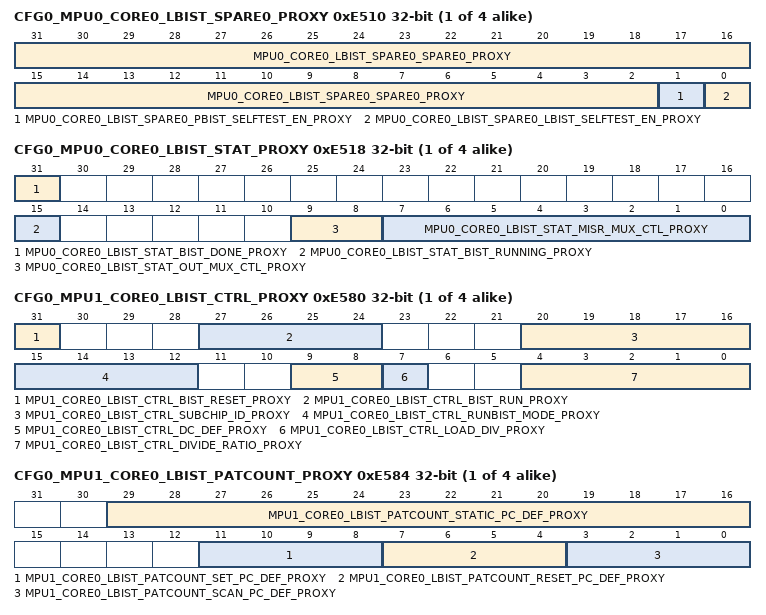
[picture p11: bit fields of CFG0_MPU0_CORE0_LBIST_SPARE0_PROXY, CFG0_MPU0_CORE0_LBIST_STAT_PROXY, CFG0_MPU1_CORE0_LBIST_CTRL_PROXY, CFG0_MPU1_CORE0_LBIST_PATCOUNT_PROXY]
{0xE510+0x20*i} CFG0_MPU0_CORE{i}_LBIST_SPARE0_PROXY (i=0..3) — Spare LBIST control bits
  [31:2] MPU0_CORE{i}_LBIST_SPARE0_SPARE0_PROXY — LBIST spare bits
  [1] MPU0_CORE{i}_LBIST_SPARE0_PBIST_SELFTEST_EN_PROXY — PBIST isolation control
  [0] MPU0_CORE{i}_LBIST_SPARE0_LBIST_SELFTEST_EN_PROXY — LBIST isolation control
{0xE514+0x20*i} CFG0_MPU0_CORE{i}_LBIST_SPARE1_PROXY (i=0..3) — Spare LBIST control bits
  [31:0] MPU0_CORE{i}_LBIST_SPARE1_SPARE1_PROXY — LBIST spare bits
{0xE518+0x20*i} CFG0_MPU0_CORE{i}_LBIST_STAT_PROXY access per field (i=0..3) — Indicates LBIST status and provides MISR selection control
  [31] MPU0_CORE{i}_LBIST_STAT_BIST_DONE_PROXY ro — LBIST is done
  [15] MPU0_CORE{i}_LBIST_STAT_BIST_RUNNING_PROXY ro — LBIST is running
  [9:8] MPU0_CORE{i}_LBIST_STAT_OUT_MUX_CTL_PROXY rw — Selects source of LBIST output 00 - LBIST IP PID value 01 - LBIST CTRL ID value 1x - MISR value
  [7:0] MPU0_CORE{i}_LBIST_STAT_MISR_MUX_CTL_PROXY rw — Selects block of 32 MISR bits to read. A value of 0 selects a compacted 32-bit version of the full MISR. A value of 1-32 select a 32-bit segment of the MISR.
{0xE51C+0x20*i} CFG0_MPU0_CORE{i}_LBIST_MISR_PROXY ro (i=0..3) — Contains LBIST MISR output value
  [31:0] MPU0_CORE{i}_LBIST_MISR_MISR_RESULT_PROXY — 32-bits of MISR value selected by misr_mux_ctl
{0xE580+0x20*i} CFG0_MPU1_CORE{i}_LBIST_CTRL_PROXY (i=0..3) — Configures and enables LBIST operation
  [31] MPU1_CORE{i}_LBIST_CTRL_BIST_RESET_PROXY — Reset LBIST macro
  [27:24] MPU1_CORE{i}_LBIST_CTRL_BIST_RUN_PROXY — Starts LBIST if all bits are 1
  [20:16] MPU1_CORE{i}_LBIST_CTRL_SUBCHIP_ID_PROXY — Specifies which sub-chip is to be tested
  [15:12] MPU1_CORE{i}_LBIST_CTRL_RUNBIST_MODE_PROXY — Runbist mode enable if all bits are 1
  [9:8] MPU1_CORE{i}_LBIST_CTRL_DC_DEF_PROXY — Clock delay after scan_enable switching
  [7] MPU1_CORE{i}_LBIST_CTRL_LOAD_DIV_PROXY — Loads LBIST clock divide ratio on transition from 0 to 1
  [4:0] MPU1_CORE{i}_LBIST_CTRL_DIVIDE_RATIO_PROXY — LBIST clock divide ratio
{0xE584+0x20*i} CFG0_MPU1_CORE{i}_LBIST_PATCOUNT_PROXY (i=0..3) — Specifies the number of LBIST patterns to run
  [29:16] MPU1_CORE{i}_LBIST_PATCOUNT_STATIC_PC_DEF_PROXY — Number of stuck-at patterns to run
  [11:8] MPU1_CORE{i}_LBIST_PATCOUNT_SET_PC_DEF_PROXY — Number of set patterns to run
  [7:4] MPU1_CORE{i}_LBIST_PATCOUNT_RESET_PC_DEF_PROXY — Number of reset patterns to run
  [3:0] MPU1_CORE{i}_LBIST_PATCOUNT_SCAN_PC_DEF_PROXY — Number of chain test patterns to run
{0xE588+0x20*i} CFG0_MPU1_CORE{i}_LBIST_SEED0_PROXY (i=0..3) — Specifies the 32 LSBs of the PRPG seed
  [31:0] MPU1_CORE{i}_LBIST_SEED0_PRPG_DEF_PROXY — Initial seed for PRPG (bits 31:0)
{0xE58C+0x20*i} CFG0_MPU1_CORE{i}_LBIST_SEED1_PROXY (i=0..3) — Specifies the 21 MSBs of the PRPG seed
  [20:0] MPU1_CORE{i}_LBIST_SEED1_PRPG_DEF_PROXY — Initial seed for PRPG (bits 52:32)
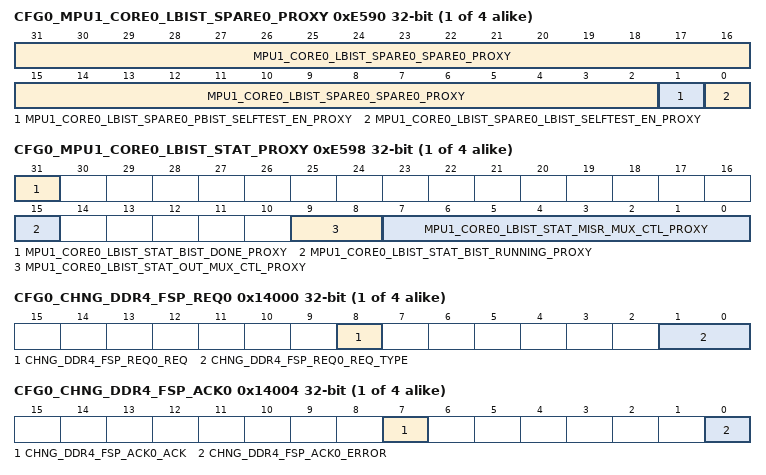
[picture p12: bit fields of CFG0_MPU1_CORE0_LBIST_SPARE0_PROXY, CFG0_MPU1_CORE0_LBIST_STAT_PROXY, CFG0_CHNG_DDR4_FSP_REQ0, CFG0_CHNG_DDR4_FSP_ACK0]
{0xE590+0x20*i} CFG0_MPU1_CORE{i}_LBIST_SPARE0_PROXY (i=0..3) — Spare LBIST control bits
  [31:2] MPU1_CORE{i}_LBIST_SPARE0_SPARE0_PROXY — LBIST spare bits
  [1] MPU1_CORE{i}_LBIST_SPARE0_PBIST_SELFTEST_EN_PROXY — PBIST isolation control
  [0] MPU1_CORE{i}_LBIST_SPARE0_LBIST_SELFTEST_EN_PROXY — LBIST isolation control
{0xE594+0x20*i} CFG0_MPU1_CORE{i}_LBIST_SPARE1_PROXY (i=0..3) — Spare LBIST control bits
  [31:0] MPU1_CORE{i}_LBIST_SPARE1_SPARE1_PROXY — LBIST spare bits
{0xE598+0x20*i} CFG0_MPU1_CORE{i}_LBIST_STAT_PROXY access per field (i=0..3) — Indicates LBIST status and provides MISR selection control
  [31] MPU1_CORE{i}_LBIST_STAT_BIST_DONE_PROXY ro — LBIST is done
  [15] MPU1_CORE{i}_LBIST_STAT_BIST_RUNNING_PROXY ro — LBIST is running
  [9:8] MPU1_CORE{i}_LBIST_STAT_OUT_MUX_CTL_PROXY rw — Selects source of LBIST output 00 - LBIST IP PID value 01 - LBIST CTRL ID value 1x - MISR value
  [7:0] MPU1_CORE{i}_LBIST_STAT_MISR_MUX_CTL_PROXY rw — Selects block of 32 MISR bits to read. A value of 0 selects a compacted 32-bit version of the full MISR. A value of 1-32 select a 32-bit segment of the MISR.
{0xE59C+0x20*i} CFG0_MPU1_CORE{i}_LBIST_MISR_PROXY ro (i=0..3) — Contains LBIST MISR output value
  [31:0] MPU1_CORE{i}_LBIST_MISR_MISR_RESULT_PROXY — 32-bits of MISR value selected by misr_mux_ctl
{0xE600+0x20*i} CFG0_MPU0_CORE{i}_LBIST_SIG_PROXY ro (i=0..3) — Contains expected MISR output value
  [31:0] MPU0_CORE{i}_LBIST_SIG_MISR_SIG_PROXY — MISR signature
{0xE680+0x20*i} CFG0_MPU1_CORE{i}_LBIST_SIG_PROXY ro (i=0..3) — Contains expected MISR output value
  [31:0] MPU1_CORE{i}_LBIST_SIG_MISR_SIG_PROXY — MISR signature
{0xF100+4i} CFG0_CLAIMREG_P3_R{i} (i=0..13)
  [31:0] CLAIMREG_P3_R{i} — Claim bits for Partition 3
{0x11100+4i} CFG0_CLAIMREG_P4_R{i}_READONLY ro (i=0..11)
  [31:0] CLAIMREG_P4_R{i}_READONLY — Claim bits for Partition 4
{0x13100+4i} CFG0_CLAIMREG_P4_R{i} (i=0..11)
  [31:0] CLAIMREG_P4_R{i} — Claim bits for Partition 4
{0x14000+0x10*i} CFG0_CHNG_DDR4_FSP_REQ{i} (i=0..3) — This register is used to initiate a LPDDR4 frequency set point change to the DDR {i} Controller
  [8] CHNG_DDR4_FSP_REQ{i}_REQ — Initiate FSP frequency change
  [1:0] CHNG_DDR4_FSP_REQ{i}_REQ_TYPE — Frequency request typeIndicates which DDR4 frequency set point to change to
{0x14004+0x10*i} CFG0_CHNG_DDR4_FSP_ACK{i} ro (i=0..3) — This register is used by the DDR {i} Controller to acknowledge the LPDDR4 frequency set point change request
  [7] CHNG_DDR4_FSP_ACK{i}_ACK — Frequency change acknowledge.This bit is only valid when CHNG_DDR4_FSP_REQ_req = 1Indication from the DDR Controller that the FSP change operation is complete 0 - FSP change operation in progress 1 - FSP change operation complete
  [0] CHNG_DDR4_FSP_ACK{i}_ERROR — Frequency change errorThis bit is only valid when CHNG_DDR4_FSP_REQ_req = 1 0 - FSP change was successful 1 - FSP change was not successful
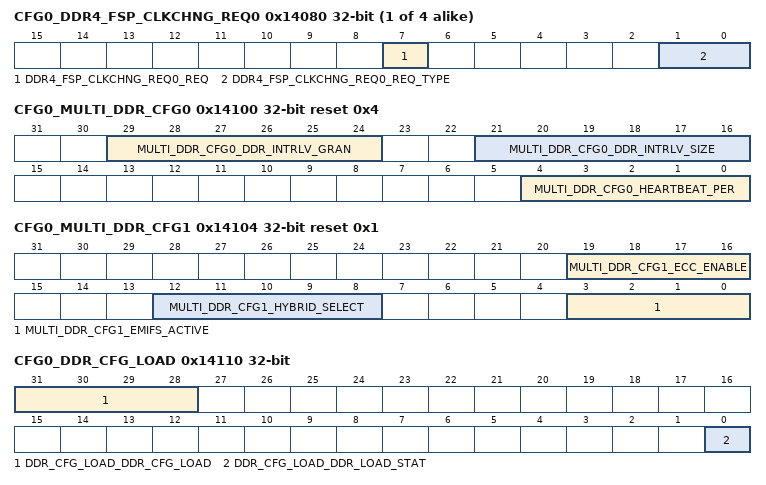
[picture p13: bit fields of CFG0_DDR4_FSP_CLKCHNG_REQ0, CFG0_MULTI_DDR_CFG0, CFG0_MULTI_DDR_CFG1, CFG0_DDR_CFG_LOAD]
{0x14080+0x10*i} CFG0_DDR4_FSP_CLKCHNG_REQ{i} ro (i=0..3) — This register is used by the DDR {i} Controller to request the DDR{i} PLL clock frequency change. This can occur as part of DDR4 initialization and training or in response to a LPDDR4 FSP change request.
  [7] DDR4_FSP_CLKCHNG_REQ{i}_REQ — DDR Controller FSP clock change requestIndicates that the DDR controller needs the DDR clock changed to the frequency indicated by the req_type field. This bit is cleared when the DDR4_FSP_CLKCHNG_ACK_ack bit is set.
  [1:0] DDR4_FSP_CLKCHNG_REQ{i}_REQ_TYPE — Frequency request typeIndicates which DDR4 FSP frequency to which the DDR Controller wants the DDR clock set
{0x140C0+0x10*i} CFG0_DDR4_FSP_CLKCHNG_ACK{i} (i=0..3) — This register is used to acknowledge a DDR{i} PLL clock frequency change to the DDR{i} Controller.
  [0] DDR4_FSP_CLKCHNG_ACK{i}_ACK — DDR FSP clock change acknowledgeThis bit should be set once the DDR clock has been successfully changed to the value requested by DDR4_FSP_CLKCHNG_REQ_req_type. Setting this bit will clear the DDR4_FSP_CLKCHNG_REQ_req bit and the associated change request interrupt.
0x14100 CFG0_MULTI_DDR_CFG0 reset 0x4 — Configures DDR interleaving
  [29:24] MULTI_DDR_CFG0_DDR_INTRLV_GRAN — Defines the size of each memory stripe for interleaved memory space. Value takes effect when MULTI_DDR_CFG1_ddr_cfg _load field is set as 4'b0110. Field values (Others are reserved): 6'b000000 - 128 B 6'b000001 - 512 B 6'b000010 - 2 KB 6'b000011 - 4 KB 6'b000100 - 16 KB 6'b000101 - 32 KB 6'b000110 - 512 MB 6'b000111 - 1 GB 6'b001000 - 1.5 GB 6'b001001 - 2 GB 6'b001010 - 3 GB 6'b001011 - 4 GB 6'b001100 - 6 GB 6'b001101 - 8 GB 6'b001110 - 16 GB
  [21:16] MULTI_DDR_CFG0_DDR_INTRLV_SIZE — Defines the memory window size for the interleaved region starting at the bottom of the external memory address range. Value takes effect when MULTI_DDR_CFG1_ddr_cfg _load field is set as 4'b0110. Field values (Others are reserved): 6'b000000 - 0 (no interleave) 6'b000001 - 128 MB 6'b000010 - 256 MB 6'b000011 - 512 MB 6'b000100 - 1 GB 6'b000101 - 2 GB 6'b000110 - 3 GB 6'b000111 - 4 GB 6'b001000 - 6 GB 6'b001001 - 8 GB 6'b001010 - 12 GB 6'b001011 - 16 GB 6'b001100 - 32 GB
  [4:0] MULTI_DDR_CFG0_HEARTBEAT_PER — Determines number of cycles of unsuccessful EMIF arbitration to wait before arbitrating for a different EMIF port. Value takes effect when MULTI_DDR_CFG1_ddr_cfg _load field is set as 4'b0110. 0 - Heartbeat is disabled 1-31 - Number of cycles before port switch
0x14104 CFG0_MULTI_DDR_CFG1 reset 0x1 — Configures DDR interleaving
  [19:16] MULTI_DDR_CFG1_ECC_ENABLE — Determines which EMIFs have ECC enabled. Value takes effect when MULTI_DDR_CFG1_ddr_cfg _load field is set as 4'b0110. Field values (Others are reserved): 4'b0000 - ECC disabled on all EMIFs 4'b0001 - ECC enabled on EMIF 0 4'b0010 - ECC enabled on EMIF 1 4'b0011 - ECC enabled on EMIF 0,1 4'b0100 - ECC enabled on EMIF 2 4'b0101 - ECC enabled on EMIF 0,2 4'b0110 - ECC enabled on EMIF 1,2 4'b0111 - ECC enabled on EMIF 0,1,2 4'b1000 - ECC enabled on EMIF 3 4'b1001 - ECC enabled on EMIF 0,3 4'b1010 - ECC enabled on EMIF 1,3 4'b1011 - ECC enabled on EMIF 0,1,3 4'b1100 - ECC enabled on EMIF 2,3 4'b1101 - ECC enabled on EMIF 0,2,3 4'b1110 - ECC enabled on EMIF 1,2,3 4'b1111 - ECC enabled on EMIF 0,1,2,3
  [12:8] MULTI_DDR_CFG1_HYBRID_SELECT — Determines interleaved EMIF space location. Usage is based on number of EMIFs present. Value takes effect when MULTI_DDR_CFG1_ddr_cfg _load field is set as 4'b0110. Field values (Others are reserved): 4'b00000 - Entire EMIF space is interleaved 4'b00001 - 2 EMIFs - EMIF 0 separated, EMIF 0,1 interleaved 4'b00001 - 3 EMIFs - EMIF 0 separated, EMIF 1,2 interleaved 4'b00001 - 4 EMIFs - EMIF 0 separated, EMIF 1,2,3 interleaved 4'b00010 - 2 EMIFs - EMIF 1 separated, EMIF 0,1 interleaved 4'b00010 - 3 EMIFs - EMIF 1 separated, EMIF 0,2 interleaved 4'b00010 - 4 EMIFs - EMIF 1 separated, EMIF 0,2,3 interleaved 4'b00100 - 2 EMIFS - reserved 4'b00100 - 3 EMIFs - EMIF 2 separated, EMIF 0,1 interleaved 4'b00100 - 4 EMIFs - EMIF 2 separated, EMIF 0,1,3 interleaved 4'b01000 - 2 EMIFS - reserved 4'b01000 - 3 EMIFS - reserved 4'b01000 - 4 EMIFs - EMIF 3 separated, EMIF 0,1,2 interleaved 4'b10000 - reserved 4'b10001 - 2 EMIFs - EMIF 0 separated, EMIF 0,1 interleaved 4'b10001 - 3 EMIFs - EMIF 0 separated, EMIF 0,1,2 interleaved 4'b10001 - 4 EMIFs - EMIF 0 separated, EMIF 0,1,2,3 interleaved 4'b10010 - 2 EMIFs - EMIF 1 separated, EMIF 0,1 interleaved 4'b10010 - 3 EMIFs - EMIF 1 separated, EMIF 0,1,2 interleaved 4'b10010 - 4 EMIFs - EMIF 1 separated, EMIF 0,1,2,3 interleaved 4'b10100 - 2 EMIFS - reserved 4'b10100 - 3 EMIFs - EMIF 2 separated, EMIF 0,1,2 interleaved 4'b10100 - 4 EMIFS - EMIF 2 separated, EMIF 0,1,2,3 interleaved 4'b11000 - 2 EMIFS - reserved 4'b11000 - 3 EMIFS - reserved 4'b11000 - 4 EMIFs - EMIF 3 separated, EMIF 0,1,2,3 interleaved
  [3:0] MULTI_DDR_CFG1_EMIFS_ACTIVE — Indicates which EMIF (DDR) interfaces are active. Value takes effect when MULTI_DDR_CFG1_ddr_cfg _load field is set as 4'b0110. Field values (Others are reserved): 4'b0000 - Reserved 4'b0001 - EMIF 0 Active 4'b0010 - EMIF 1 Active 4'b0011 - EMIF 0,1 Active 4'b0100 - EMIF 2 Active 4'b0101 - EMIF 0,2 Active 4'b0110 - EMIF 1,2 Active 4'b0111 - EMIF 0,1,2 Active 4'b1000 - EMIF 3 Active 4'b1001 - EMIF 0,3 Active 4'b1010 - EMIF 1,3 Active 4'b1011 - EMIF 0,1,3 Active 4'b1100 - EMIF 2,3 Active 4'b1101 - EMIF 0,2,3 Active 4'b1110 - EMIF 1,2,3 Active 4'b1111 - EMIF 0,1,2,3 Active
0x14110 CFG0_DDR_CFG_LOAD access per field — Implements Multi-DDR configuration load and load status
  [31:28] DDR_CFG_LOAD_DDR_CFG_LOAD rw — When set to 4'b0110, latches the ddr configuration bits into ComputeCluster. Once latched, the ComputeCluster ignores further transitions on its latch input so any further changes to this field have no effect.
  [0] DDR_CFG_LOAD_DDR_LOAD_STAT ro — DDR configuration lock status bit indicating that DDR config load is complete
0x15008 CFG0_LOCK5_KICK0 — This register must be written with the designated key value followed by a write to LOCK5_KICK1 with its key value before write-protected Partition 5 registers can be written.
  [31:0] LOCK5_KICK0 — - KICK0 component
0x1500C CFG0_LOCK5_KICK1 — This register must be written with the designated key value after a write to LOCK5_KICK0 with its key value before write-protected Partition 5 registers can be written.
  [31:0] LOCK5_KICK1 — - KICK1 component
{0x15100+4i} CFG0_CLAIMREG_P5_R{i}_READONLY ro (i=0..2)
  [31:0] CLAIMREG_P5_R{i}_READONLY — Claim bits for Partition 5
